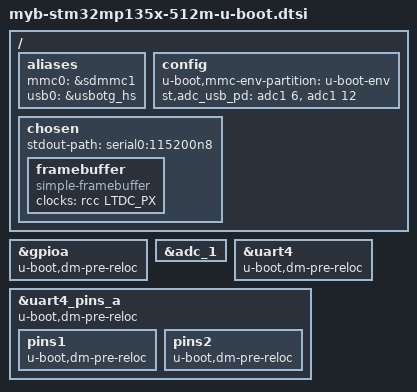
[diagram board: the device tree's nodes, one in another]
// SPDX-License-Identifier: GPL-2.0-or-later OR BSD-3-Clause
/*
 * Copyright (C) STMicroelectronics 2021 - All Rights Reserved
 */

#include "stm32mp13-u-boot.dtsi"

/ {
	aliases {
		mmc0 = &sdmmc1;
		usb0 = &usbotg_hs;
	};

	config {
		u-boot,mmc-env-partition = "u-boot-env";
		st,adc_usb_pd = <&adc1 6>, <&adc1 12>;
	};

	chosen {
		#address-cells = <1>;
		#size-cells = <1>;
		ranges;
		stdout-path = "serial0:115200n8";

		framebuffer {
			compatible = "simple-framebuffer";
			clocks = <&rcc LTDC_PX>;
			status = "okay";
		};
	};
};

/* 确保 GPIOA 控制器本身在早期阶段可用 */
&gpioa {
	u-boot,dm-pre-reloc;
};

&adc_1 {
	status = "okay";
};

&uart4 {
	u-boot,dm-pre-reloc;
};

&uart4_pins_a {
	u-boot,dm-pre-reloc;
	pins1 {
		u-boot,dm-pre-reloc;
	};
	pins2 {
		u-boot,dm-pre-reloc;
	};
};
